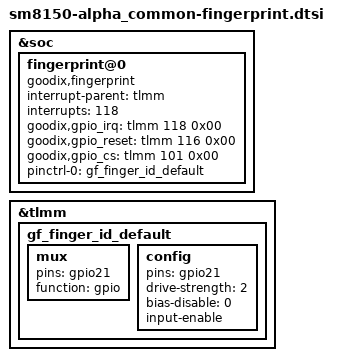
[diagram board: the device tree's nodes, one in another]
/*
 * Copyright (c) 2018, The Linux Foundation. All rights reserved.
 *
 * This program is free software; you can redistribute it and/or modify
 * it under the terms of the GNU General Public License version 2 and
 * only version 2 as published by the Free Software Foundation.
 *
 * This program is distributed in the hope that it will be useful,
 * but WITHOUT ANY WARRANTY; without even the implied warranty of
 * MERCHANTABILITY or FITNESS FOR A PARTICULAR PURPOSE.  See the
 * GNU General Public License for more details.
 */

#include "../../sm8150_common/sm8150_common-fingerprint.dtsi"

&soc {
	fingerprint@0 {
		status = "ok";
    		compatible = "goodix,fingerprint";

		interrupt-parent = <&tlmm>;
		interrupts = <118>;

		goodix,gpio_irq = <&tlmm 118 0x00>;
		goodix,gpio_reset = <&tlmm 116 0x00>;
		goodix,gpio_cs  = <&tlmm 101 0x00>;
		pinctrl-names = "default";
		pinctrl-0 = <&gf_finger_id_default>; /* GIPO 21 */
	};
};

&tlmm {
	gf_finger_id_default: gf_finger_id_default {
		mux {
			pins = "gpio21";
			function = "gpio";
		};
		config {
			pins = "gpio21";
			drive-strength = <2>; /* 2 mA */
			bias-disable = <0>;   /* no pull */
			input-enable;
		};
	};
};
